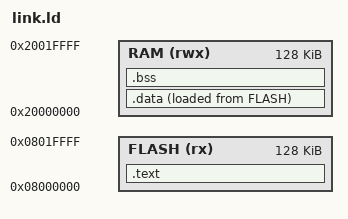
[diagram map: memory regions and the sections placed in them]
ENTRY(Reset_Handler)

MEMORY
{
  /* 128K is safe for every G0B1 variant (CB=128K, CE=512K). Raise it if yours is bigger. */
  FLASH (rx)  : ORIGIN = 0x08000000, LENGTH = 128K
  RAM   (rwx) : ORIGIN = 0x20000000, LENGTH = 128K
}

_estack = ORIGIN(RAM) + LENGTH(RAM);

SECTIONS
{
  .text :
  {
    KEEP(*(.isr_vector))
    *(.text*)
    *(.rodata*)
    . = ALIGN(4);
  } > FLASH

  _sidata = LOADADDR(.data);

  .data :
  {
    _sdata = .;
    *(.data*)
    . = ALIGN(4);
    _edata = .;
  } > RAM AT > FLASH

  .bss :
  {
    _sbss = .;
    *(.bss*)
    *(COMMON)
    . = ALIGN(4);
    _ebss = .;
  } > RAM

  /DISCARD/ : { *(.ARM.exidx*) *(.note*) *(.comment*) }
}
